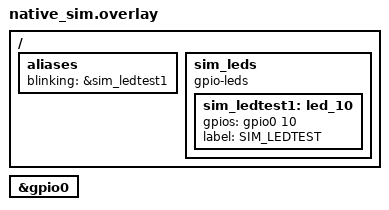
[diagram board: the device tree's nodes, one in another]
/ {
    aliases {
        blinking = &sim_ledtest1;
    };

    sim_leds {
        compatible = "gpio-leds";
        sim_ledtest1: led_10 {
            gpios = <&gpio0 10 GPIO_ACTIVE_HIGH>;
            label = "SIM_LEDTEST";
        };
    };
};

&gpio0 {
    status = "okay";
};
